# STM32F103 register map
File version: 1.0
CPU: CM3 r1p1, little endian, 4 interrupt priority bits
Registers are 32-bit, read-write, reset 0x0 unless marked. A register's access mark holds for its fields unless they carry their own. Offsets are from the block's base; [hi:lo] are bit positions; {n}, {i} and the like mark numbered series; 'fields as' and 'values as' point back to an identical list.

## NVIC — Nested Vectored Interrupt Controller
Base 0xE000ED00
0x04 ICTR ro — Interrupt Controller Type Register
  [3:0] INTLINESNUM — Total number of interrupt lines in groups
0x100 ISER0 — Interrupt Set-Enable Register
  [31:0] SETENA
0x104 ISER1 — Interrupt Set-Enable Register
  [31:0] SETENA
0x180 ICER0 — Interrupt Clear-Enable Register
  [31:0] CLRENA
0x184 ICER1 — Interrupt Clear-Enable Register
  [31:0] CLRENA
0x200 ISPR0 — Interrupt Set-Pending Register
  [31:0] SETPEND
0x204 ISPR1 — Interrupt Set-Pending Register
  [31:0] SETPEND
0x280 ICPR0 — Interrupt Clear-Pending Register
  [31:0] CLRPEND
0x284 ICPR1 — Interrupt Clear-Pending Register
  [31:0] CLRPEND
0x300 IABR0 ro — Interrupt Active Bit Register
  [31:0] ACTIVE
0x304 IABR1 ro — Interrupt Active Bit Register
  [31:0] ACTIVE
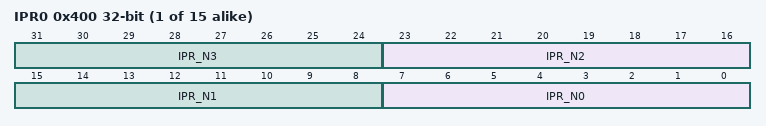
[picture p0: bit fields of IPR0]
{0x400+4i} IPR{i} (i=0..14) — Interrupt Priority Register
  [8n+7:8n] IPR_N{n} (n=0..3)
0xF00 STIR wo — Software Triggered Interrupt Register
  [8:0] INTID — interrupt to be triggered

## USB — Universal serial bus full-speed device interface
Base 0x40005C00
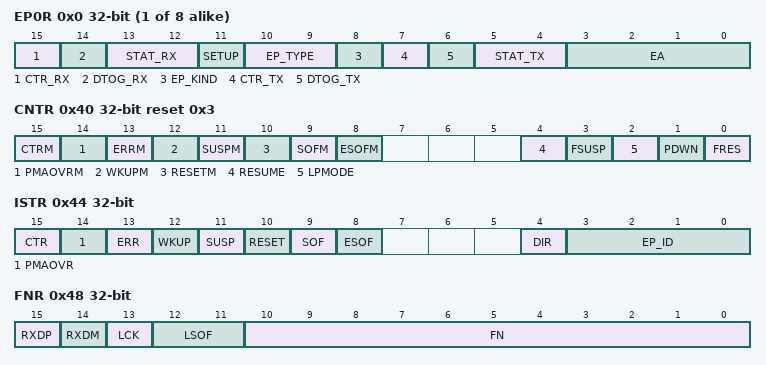
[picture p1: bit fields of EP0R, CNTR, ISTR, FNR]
{0x0+4i} EP{i}R (i=0..7) — endpoint {i} register
  [15] CTR_RX — Correct transfer for reception
  [14] DTOG_RX — Data Toggle, for reception transfers
  [13:12] STAT_RX — Status bits, for reception transfers
  [11] SETUP — Setup transaction completed
  [10:9] EP_TYPE — Endpoint type
  [8] EP_KIND — Endpoint kind
  [7] CTR_TX — Correct Transfer for transmission
  [6] DTOG_TX — Data Toggle, for transmission transfers
  [5:4] STAT_TX — Status bits, for transmission transfers
  [3:0] EA — Endpoint address
0x40 CNTR reset 0x3 — control register
  [15] CTRM — Correct transfer interrupt mask
  [14] PMAOVRM — Packet memory area over / underrun interrupt mask
  [13] ERRM — Error interrupt mask
  [12] WKUPM — Wakeup interrupt mask
  [11] SUSPM — Suspend mode interrupt mask
  [10] RESETM — USB reset interrupt mask
  [9] SOFM — Start of frame interrupt mask
  [8] ESOFM — Expected start of frame interrupt mask
  [4] RESUME — Resume request
  [3] FSUSP — Force suspend
  [2] LPMODE — Low-power mode
  [1] PDWN — Power down
  [0] FRES — Force USB Reset
0x44 ISTR — interrupt status register
  [15] CTR — Correct transfer
  [14] PMAOVR — Packet memory area over / underrun
  [13] ERR — Error
  [12] WKUP — Wakeup
  [11] SUSP — Suspend mode request
  [10] RESET — reset request
  [9] SOF — start of frame
  [8] ESOF — Expected start frame
  [4] DIR — Direction of transaction
  [3:0] EP_ID — Endpoint Identifier
0x48 FNR ro — frame number register
  [15] RXDP — Receive data + line status
  [14] RXDM — Receive data - line status
  [13] LCK — Locked
  [12:11] LSOF — Lost SOF
  [10:0] FN — Frame number
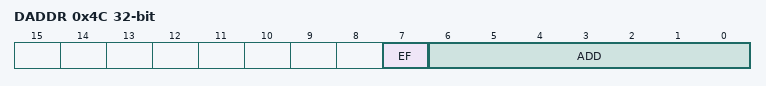
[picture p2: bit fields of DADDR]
0x4C DADDR — device address
  [7] EF — Enable function
  [6:0] ADD — Device address
0x50 BTABLE — Buffer table address
  [15:3] BTABLE — Buffer table

## OTG_FS_HOST — USB on the go full speed
Base 0x50000400
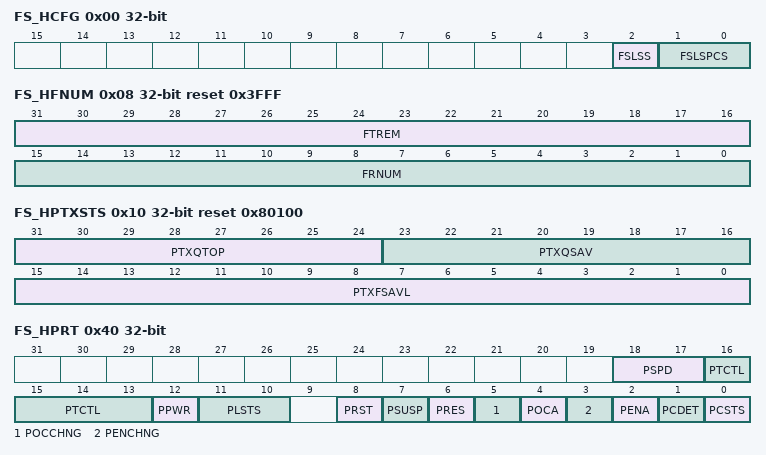
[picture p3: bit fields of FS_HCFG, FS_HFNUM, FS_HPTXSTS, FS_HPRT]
0x00 FS_HCFG access per field — OTG_FS host configuration register (OTG_FS_HCFG)
  [2] FSLSS ro — FS- and LS-only support
  [1:0] FSLSPCS rw — FS/LS PHY clock select
0x04 HFIR reset 0xEA60 — OTG_FS Host frame interval register
  [15:0] FRIVL — Frame interval
0x08 FS_HFNUM ro reset 0x3FFF — OTG_FS host frame number/frame time remaining register (OTG_FS_HFNUM)
  [31:16] FTREM — Frame time remaining
  [15:0] FRNUM — Frame number
0x10 FS_HPTXSTS access per field reset 0x80100 — OTG_FS_Host periodic transmit FIFO/queue status register (OTG_FS_HPTXSTS)
  [31:24] PTXQTOP ro — Top of the periodic transmit request queue
  [23:16] PTXQSAV ro — Periodic transmit request queue space available
  [15:0] PTXFSAVL rw — Periodic transmit data FIFO space available
0x14 HAINT ro — OTG_FS Host all channels interrupt register
  [15:0] HAINT — Channel interrupts
0x18 HAINTMSK — OTG_FS host all channels interrupt mask register
  [15:0] HAINTM — Channel interrupt mask
0x40 FS_HPRT access per field — OTG_FS host port control and status register (OTG_FS_HPRT)
  [18:17] PSPD ro — Port speed
  [16:13] PTCTL rw — Port test control
  [12] PPWR rw — Port power
  [11:10] PLSTS ro — Port line status
  [8] PRST rw — Port reset
  [7] PSUSP rw — Port suspend
  [6] PRES rw — Port resume
  [5] POCCHNG rw — Port overcurrent change
  [4] POCA ro — Port overcurrent active
  [3] PENCHNG rw — Port enable/disable change
  [2] PENA rw — Port enable
  [1] PCDET rw — Port connect detected
  [0] PCSTS ro — Port connect status
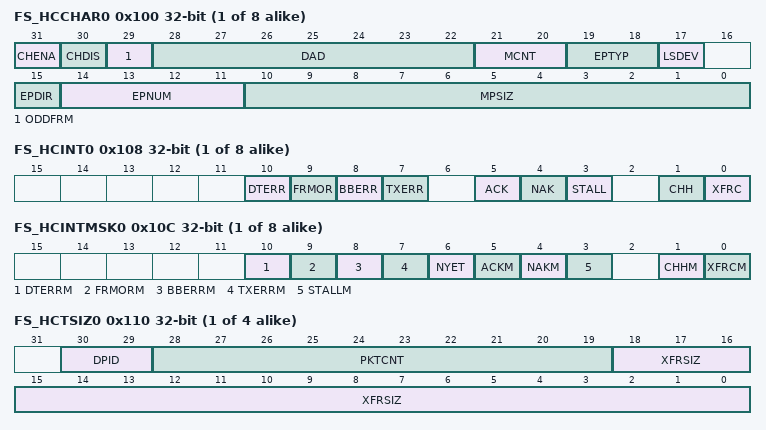
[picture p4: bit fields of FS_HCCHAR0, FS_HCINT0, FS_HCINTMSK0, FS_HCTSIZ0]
{0x100+0x20*i} FS_HCCHAR{i} (i=0..7) — OTG_FS host channel-{i} characteristics register (OTG_FS_HCCHAR{i})
  [31] CHENA — Channel enable
  [30] CHDIS — Channel disable
  [29] ODDFRM — Odd frame
  [28:22] DAD — Device address
  [21:20] MCNT — Multicount
  [19:18] EPTYP — Endpoint type
  [17] LSDEV — Low-speed device
  [15] EPDIR — Endpoint direction
  [14:11] EPNUM — Endpoint number
  [10:0] MPSIZ — Maximum packet size
{0x108+0x20*i} FS_HCINT{i} (i=0..7) — OTG_FS host channel-{i} interrupt register (OTG_FS_HCINT{i})
  [10] DTERR — Data toggle error
  [9] FRMOR — Frame overrun
  [8] BBERR — Babble error
  [7] TXERR — Transaction error
  [5] ACK — ACK response received/transmitted interrupt
  [4] NAK — NAK response received interrupt
  [3] STALL — STALL response received interrupt
  [1] CHH — Channel halted
  [0] XFRC — Transfer completed
{0x10C+0x20*i} FS_HCINTMSK{i} (i=0..7) — OTG_FS host channel-{i} mask register (OTG_FS_HCINTMSK{i})
  [10] DTERRM — Data toggle error mask
  [9] FRMORM — Frame overrun mask
  [8] BBERRM — Babble error mask
  [7] TXERRM — Transaction error mask
  [6] NYET — response received interrupt mask
  [5] ACKM — ACK response received/transmitted interrupt mask
  [4] NAKM — NAK response received interrupt mask
  [3] STALLM — STALL response received interrupt mask
  [1] CHHM — Channel halted mask
  [0] XFRCM — Transfer completed mask
{0x110+0x20*i} FS_HCTSIZ{i} (i=0..3) — OTG_FS host channel-{i} transfer size register
  [30:29] DPID — Data PID
  [28:19] PKTCNT — Packet count
  [18:0] XFRSIZ — Transfer size
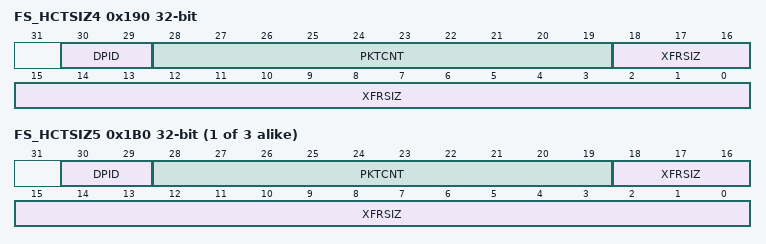
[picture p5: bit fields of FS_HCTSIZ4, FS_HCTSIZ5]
0x190 FS_HCTSIZ4 — OTG_FS host channel-x transfer size register
  fields as FS_HCTSIZ0
{0x110+0x20*i} FS_HCTSIZ{i} (i=5..7) — OTG_FS host channel-{i} transfer size register
  fields as FS_HCTSIZ0
